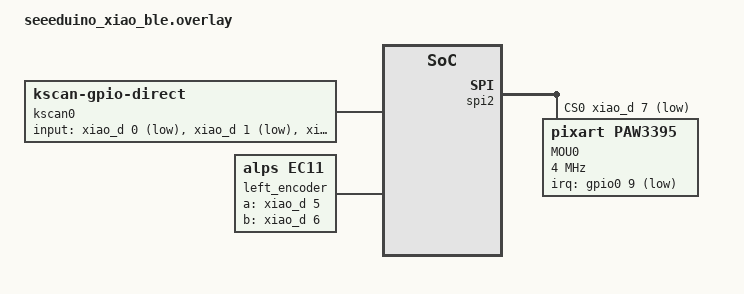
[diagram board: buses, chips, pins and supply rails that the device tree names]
#include <dt-bindings/zmk/matrix_transform.h>
#include <zephyr/dt-bindings/input/input-event-codes.h>
#include <input/processors.dtsi>
#include <dt-bindings/zmk/input_transform.h>

/ {
    /* 
     * Map XIAO on-board RGB LEDs (led0-2) for zmk-rgbled-widget
     * XIAO内蔵の3色LED（led0〜2）を zmk-rgbled-widget 用の名前に紐付け
     */
    aliases {
        led-red = &led0;
        led-green = &led1;
        led-blue = &led2;
    };

    chosen {
        zmk,kscan = &kscan0;
    };

    /* 
     * 5 Direct GPIO Button Configuration (D0 - D4)
     * 5つのボタン設定 (D0〜D4)
     */
    kscan0: kscan {
        compatible = "zmk,kscan-gpio-direct";
        wakeup-source;
        input-gpios
            = <&xiao_d 0 (GPIO_ACTIVE_LOW | GPIO_PULL_UP)> /* SW1: Left Click (Kailh Silent) / 左クリック */
            , <&xiao_d 1 (GPIO_ACTIVE_LOW | GPIO_PULL_UP)> /* SW2: Right Click (Kailh Silent) / 右クリック */
            , <&xiao_d 2 (GPIO_ACTIVE_LOW | GPIO_PULL_UP)> /* SW3: Middle Click (Short Tactile H=4.3mm) / 中クリック */
            , <&xiao_d 3 (GPIO_ACTIVE_LOW | GPIO_PULL_UP)> /* SW4: Side Button (Kailh Silent) / サイドボタン */
            , <&xiao_d 4 (GPIO_ACTIVE_LOW | GPIO_PULL_UP)> /* SW5: Mode Button (Tall Tactile H=5.0mm) / モードボタン */
            ;
    };

    /* 
     * TTC Green Core Mechanical Rotary Encoder (12 Pulses / 24 Detents)
     * TTC グリーンコア エンコーダ設定 (仕様: 12パルス / 24デテント)
     */
    /*
     * =========================================================================
     * [Hardware Spec] TTC Green Core Mechanical Rotary Encoder
     * -------------------------------------------------------------------------
     * [Pins / ピン配置]:
     *   - Channel A: D5 (P0.02)
     *   - Channel B: D6 (P0.03)
     *
     * [Detents vs Pulses / パルスとデテントの整合性]:
     *   TTC グリーンコアは 1回転あたり「24ノッチ（デテント）」に対し、
     *   電気信号は「12パルス（周期）」を出力する仕様。
     *   - `steps = <12>;` (ドライバー層のパルス数定義)
     *   - `triggers-per-rotation = <24>;` (ZMKセンサー層のノッチ数定義)
     *   この 12 : 24 の比率に設定することで、物理的に「カチッ」と1目盛り回した
     *   時にちょうど1回だけスクロール信号が発火します。
     * =========================================================================
     */
    left_encoder: encoder_left {
        compatible = "alps,ec11";
        a-gpios = <&xiao_d 5 (GPIO_ACTIVE_HIGH | GPIO_PULL_UP)>;
        b-gpios = <&xiao_d 6 (GPIO_ACTIVE_HIGH | GPIO_PULL_UP)>;
        steps = <12>; /* 12 pulses per rotation / 12パルス指定（1ノッチ＝1発火に一致） */
        status = "okay";
    };

    sensors: sensors {
        compatible = "zmk,keymap-sensors";
        sensors = <&left_encoder>;
        triggers-per-rotation = <24>; /* 24 physical detents / 24デテント指定 */
    };

    /* 
     * Sensor Input Listener (Drag Scroll Mapper on Layer 2)
     * PAW3395 入力リスナー設定（レイヤー2でのセンサースクロール変換）
     */
    paw3395_listener {
        compatible = "zmk,input-listener";
        device = <&pd0>;

        /* 
         * Layer 2 (Side + Hold Right Click): Omnidirectional drag scroll
         * レイヤー2（サイド＋右クリック中）：上下左右すべて自由に動く高速スクロール
         */
        drag_scroll_fast {
            layers = <2>;
            input-processors = <&zip_xy_scaler 1 1>, <&zip_xy_transform (INPUT_TRANSFORM_X_INVERT | INPUT_TRANSFORM_Y_INVERT)>, <&zip_xy_to_scroll_mapper>;
        };
    };
};

/* Disable unused I2C0 / 未使用のI2C0を無効化 */
&i2c0 {
    status = "disabled";
};

/* 
 * Hardware SPI2 Bus Configuration for PixArt PAW3395 Optical Sensor
 * PAW3395 光学センサー用 ハードウェアSPI2通信設定
 */
&spi2 {
    compatible = "nordic,nrf-spim";
    status = "okay";
    cs-gpios = <&xiao_d 7 GPIO_ACTIVE_LOW>;

    pd0: pd@0 {
        compatible = "pixart,paw3395";
        status = "okay";
        label = "MOU0";
        reg = <0>;
        spi-max-frequency = <4000000>;
        irq-gpios = <&gpio0 9 (GPIO_ACTIVE_LOW | GPIO_PULL_UP)>; /* P0.09 (NFC1 pin) as motion interrupt */
        cpi = <1000>;
        evt-type = <INPUT_EV_REL>;
        x-input-code = <INPUT_REL_X>;
        y-input-code = <INPUT_REL_Y>;
        invert-x;
    };
};
